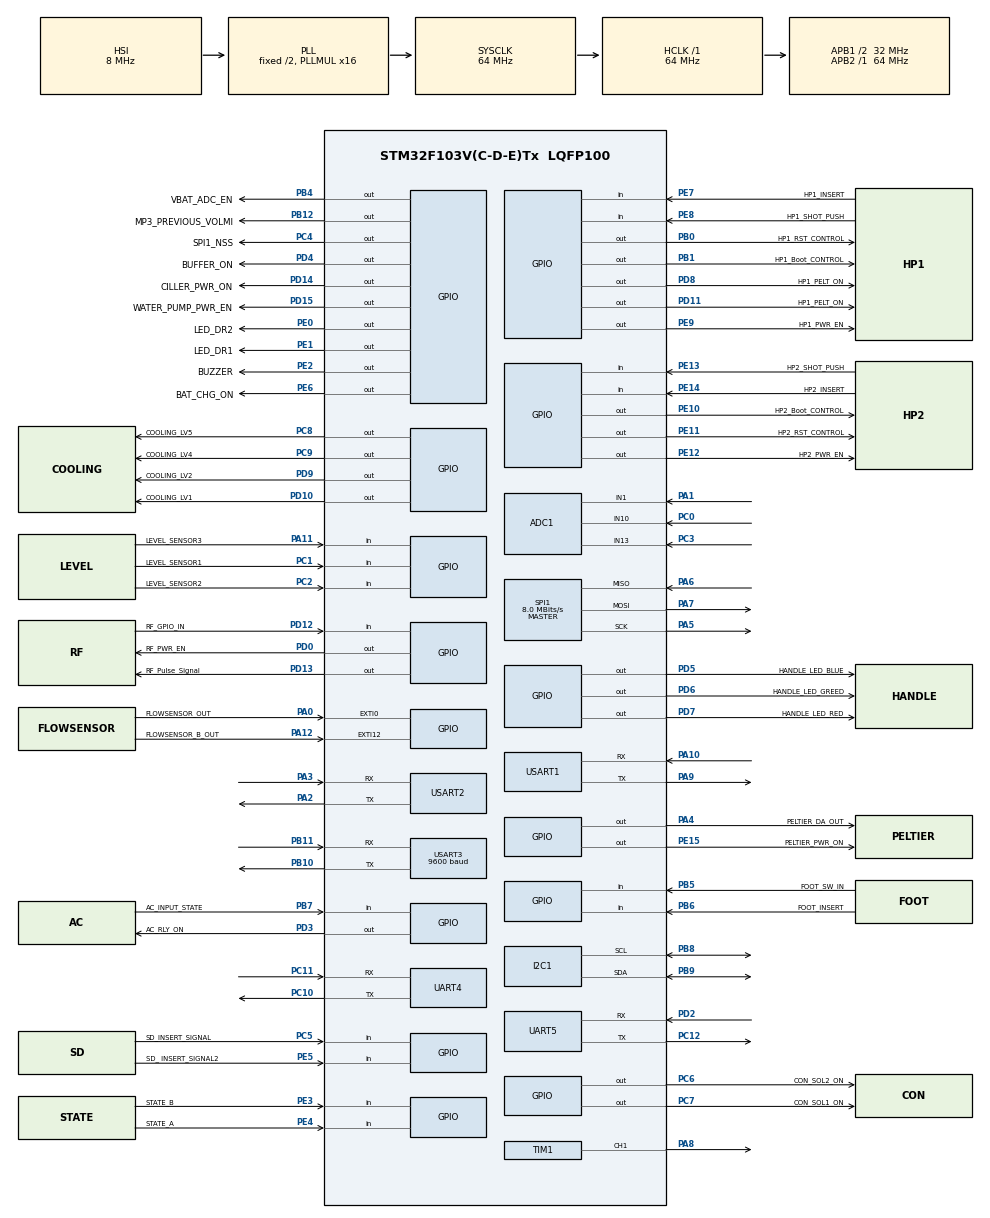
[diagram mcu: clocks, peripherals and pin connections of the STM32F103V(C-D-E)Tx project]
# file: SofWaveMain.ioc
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ADC1.Channel-0\#ChannelRegularConversion=ADC_CHANNEL_10
ADC1.NbrOfConversionFlag=1
ADC1.Rank-0\#ChannelRegularConversion=1
ADC1.SamplingTime-0\#ChannelRegularConversion=ADC_SAMPLETIME_1CYCLE_5
ADC1.master=1
FATFS._USE_LFN=1
Mcu.Family=STM32F1
Mcu.Name=STM32F103V(C-D-E)Tx
Mcu.Package=LQFP100
NVIC.EXTI0_IRQn=true\:0\:0\:false\:false\:true\:true\:true\:true
NVIC.PriorityGroup=NVIC_PRIORITYGROUP_4
NVIC.UART4_IRQn=true\:0\:0\:false\:false\:true\:true\:true\:true
NVIC.UART5_IRQn=true\:0\:0\:false\:false\:true\:true\:true\:true
NVIC.USART1_IRQn=true\:0\:0\:false\:false\:true\:true\:true\:true
NVIC.USART2_IRQn=true\:0\:0\:false\:false\:true\:true\:true\:true
NVIC.USART3_IRQn=true\:0\:0\:false\:false\:true\:true\:true\:true
PA0-WKUP.GPIO_Label=FLOWSENSOR_OUT
PA0-WKUP.Signal=GPXTI0
PA1.Signal=ADCx_IN1
PA10.Mode=Asynchronous
PA10.Signal=USART1_RX
PA11.GPIO_Label=LEVEL_SENSOR3
PA11.Signal=GPIO_Input
PA12.GPIO_Label=FLOWSENSOR_B_OUT
PA12.Signal=GPXTI12
PA13.Mode=Serial_Wire
PA13.Signal=SYS_JTMS-SWDIO
PA14.Mode=Serial_Wire
PA14.Signal=SYS_JTCK-SWCLK
PA2.Mode=Asynchronous
PA2.Signal=USART2_TX
PA3.Mode=Asynchronous
PA3.Signal=USART2_RX
PA4.GPIO_Label=PELTIER_DA_OUT
PA4.Signal=GPIO_Output
PA5.Mode=Full_Duplex_Master
PA5.Signal=SPI1_SCK
PA6.Mode=Full_Duplex_Master
PA6.Signal=SPI1_MISO
PA7.Mode=Full_Duplex_Master
PA7.Signal=SPI1_MOSI
PA8.Signal=S_TIM1_CH1
PA9.Mode=Asynchronous
PA9.Signal=USART1_TX
PB0.GPIO_Label=HP1_RST_CONTROL
PB0.Signal=GPIO_Output
PB1.GPIO_Label=HP1_Boot_CONTROL
PB1.PinState=GPIO_PIN_RESET
PB1.Signal=GPIO_Output
PB10.Mode=Asynchronous
PB10.Signal=USART3_TX
PB11.Mode=Asynchronous
PB11.Signal=USART3_RX
PB12.GPIO_Label=MP3_PREVIOUS_VOLMI
PB12.Signal=GPIO_Output
PB4.GPIO_Label=VBAT_ADC_EN
PB4.Signal=GPIO_Output
PB5.GPIO_Label=FOOT_SW_IN
PB5.Signal=GPIO_Input
PB6.GPIO_Label=FOOT_INSERT
PB6.Signal=GPIO_Input
PB7.GPIO_Label=AC_INPUT_STATE
PB7.Signal=GPIO_Input
PB8.Mode=I2C
PB8.Signal=I2C1_SCL
PB9.Mode=I2C
PB9.Signal=I2C1_SDA
PC0.Signal=ADCx_IN10
PC1.GPIO_Label=LEVEL_SENSOR1
PC1.Signal=GPIO_Input
PC10.Mode=Asynchronous
PC10.Signal=UART4_TX
PC11.Mode=Asynchronous
PC11.Signal=UART4_RX
PC12.Mode=Asynchronous
PC12.Signal=UART5_TX
PC2.GPIO_Label=LEVEL_SENSOR2
PC2.Signal=GPIO_Input
PC3.Signal=ADCx_IN13
PC4.GPIO_Label=SPI1_NSS
PC4.PinState=GPIO_PIN_SET
PC4.Signal=GPIO_Output
PC5.GPIO_Label=SD_INSERT_SIGNAL
PC5.Signal=GPIO_Input
PC6.GPIO_Label=CON_SOL2_ON
PC6.Signal=GPIO_Output
PC7.GPIO_Label=CON_SOL1_ON
PC7.Signal=GPIO_Output
PC8.GPIO_Label=COOLING_LV5
PC8.Signal=GPIO_Output
PC9.GPIO_Label=COOLING_LV4
PC9.Signal=GPIO_Output
PD0.GPIO_Label=RF_PWR_EN
PD0.Signal=GPIO_Output
PD10.GPIO_Label=COOLING_LV1
PD10.Signal=GPIO_Output
PD11.GPIO_Label=HP1_PELT_ON
PD11.Signal=GPIO_Output
PD12.GPIO_Label=RF_GPIO_IN
PD12.Signal=GPIO_Input
PD13.GPIO_Label=RF_Pulse_Signal
PD13.Signal=GPIO_Output
PD14.GPIO_Label=CILLER_PWR_ON
PD14.Signal=GPIO_Output
PD15.GPIO_Label=WATER_PUMP_PWR_EN
PD15.Signal=GPIO_Output
PD2.Mode=Asynchronous
PD2.Signal=UART5_RX
PD3.GPIO_Label=AC_RLY_ON
PD3.Signal=GPIO_Output
PD4.GPIO_Label=BUFFER_ON
PD4.Signal=GPIO_Output
PD5.GPIO_Label=HANDLE_LED_BLUE
PD5.Signal=GPIO_Output
PD6.GPIO_Label=HANDLE_LED_GREED
PD6.Signal=GPIO_Output
PD7.GPIO_Label=HANDLE_LED_RED
PD7.Signal=GPIO_Output
PD8.GPIO_Label=HP1_PELT_ON
PD8.Signal=GPIO_Output
PD9.GPIO_Label=COOLING_LV2
PD9.Signal=GPIO_Output
PE0.GPIO_Label=LED_DR2
PE0.Signal=GPIO_Output
PE1.GPIO_Label=LED_DR1
PE1.Signal=GPIO_Output
PE10.GPIO_Label=HP2_Boot_CONTROL
PE10.Signal=GPIO_Output
PE11.GPIO_Label=HP2_RST_CONTROL
PE11.Signal=GPIO_Output
PE12.GPIO_Label=HP2_PWR_EN
PE12.Signal=GPIO_Output
PE13.GPIO_Label=HP2_SHOT_PUSH
PE13.Signal=GPIO_Input
PE14.GPIO_Label=HP2_INSERT
PE14.Signal=GPIO_Input
PE15.GPIO_Label=PELTIER_PWR_ON
PE15.Signal=GPIO_Output
PE2.GPIO_Label=BUZZER
PE2.Signal=GPIO_Output
PE3.GPIO_Label=STATE_B
PE3.Signal=GPIO_Input
PE4.GPIO_Label=STATE_A
PE4.Signal=GPIO_Input
PE5.GPIO_Label=SD_ INSERT_SIGNAL2
PE5.Signal=GPIO_Input
PE6.GPIO_Label=BAT_CHG_ON
PE6.Signal=GPIO_Output
PE7.GPIO_Label=HP1_INSERT
PE7.Signal=GPIO_Input
PE8.GPIO_Label=HP1_SHOT_PUSH
PE8.Signal=GPIO_Input
PE9.GPIO_Label=HP1_PWR_EN
PE9.Signal=GPIO_Output
ProjectManager.HeapSize=0x200
ProjectManager.StackSize=0x400
ProjectManager.TargetToolchain=STM32CubeIDE
RCC.ADCPresc=RCC_ADCPCLK2_DIV6
RCC.AHBFreq_Value=64000000
RCC.APB1CLKDivider=RCC_HCLK_DIV2
RCC.APB1Freq_Value=32000000
RCC.APB1TimFreq_Value=64000000
RCC.APB2Freq_Value=64000000
RCC.APB2TimFreq_Value=64000000
RCC.HCLKFreq_Value=64000000
RCC.PLLMUL=RCC_PLL_MUL16
RCC.SYSCLKFreq_VALUE=64000000
RCC.SYSCLKSource=RCC_SYSCLKSOURCE_PLLCLK
RCC.USBFreq_Value=64000000
SH.ADCx_IN1.0=ADC1_IN1,IN1
SH.ADCx_IN10.0=ADC1_IN10,IN10
SH.ADCx_IN13.0=ADC1_IN13,IN13
SH.S_TIM1_CH1.0=TIM1_CH1,PWM Generation1 CH1
SPI1.BaudRatePrescaler=SPI_BAUDRATEPRESCALER_8
SPI1.CalculateBaudRate=8.0 MBits/s
SPI1.Direction=SPI_DIRECTION_2LINES
SPI1.Mode=SPI_MODE_MASTER
SPI1.VirtualType=VM_MASTER
TIM1.AutoReloadPreload=TIM_AUTORELOAD_PRELOAD_ENABLE
TIM1.AutomaticOutput=TIM_AUTOMATICOUTPUT_ENABLE
TIM1.Channel-PWM\ Generation1\ CH1=TIM_CHANNEL_1
TIM1.Period=9999
TIM1.Prescaler=63
TIM1.Pulse-PWM\ Generation1\ CH1=5000
UART4.VirtualMode=Asynchronous
UART5.VirtualMode=Asynchronous
USART1.VirtualMode=VM_ASYNC
USART2.VirtualMode=VM_ASYNC
USART3.BaudRate=9600
USART3.VirtualMode=VM_ASYNC
VP_FATFS_VS_Generic.Mode=User_defined
board=custom

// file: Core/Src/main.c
/* USER CODE BEGIN Header */
/**
  ******************************************************************************
  * @file           : main.c
  * @brief          : Main program body
  ******************************************************************************
  * @attention
  *
  * Copyright (c) 2025 STMicroelectronics.
  * All rights reserved.
  *
  * This software is licensed under terms that can be found in the LICENSE file
  * in the root directory of this software component.
  * If no LICENSE file comes with this software, it is provided AS-IS.
  *
  ******************************************************************************
  */
/* USER CODE END Header */
#include "main.h"
#include "adc.h"
#include "fatfs.h"
#include "i2c.h"
#include "spi.h"
#include "tim.h"
#include "usart.h"
#include "gpio.h"

/* USER CODE BEGIN Includes */
#include "common.h"//
/* USER CODE END Includes */

void SystemClock_Config(void);

int main(void)
{

  /* USER CODE BEGIN 1 */
  SCB->VTOR = 0x08010000U;//

  /* USER CODE END 1 */

  /* MCU Configuration--------------------------------------------------------*/

  /* Reset of all peripherals, Initializes the Flash interface and the Systick. */
  HAL_Init();

  /* Configure the system clock */
  SystemClock_Config();

  /* Initialize all configured peripherals */
  MX_GPIO_Init();
  MX_UART5_Init();
  MX_USART1_UART_Init();
  MX_USART2_UART_Init();
  MX_USART3_UART_Init();
  MX_UART4_Init();
  MX_ADC1_Init();
  MX_I2C1_Init();
  MX_SPI1_Init();
  MX_TIM1_Init();
  MX_FATFS_Init();
  /* USER CODE BEGIN 2 */
  Uart_Init();
  Eeprom_All_Read();
  Rf_Init();
  IO_Init();
  Hand_Init();
  LCD_Init();
  SD_Init();

//  HAL_Delay(5000);

  /* USER CODE END 2 */

  /* Infinite loop */
  /* USER CODE BEGIN WHILE */
  while (1)//
  {
    /* USER CODE END WHILE */

    /* USER CODE BEGIN 3 */

#if 1
  IO_Config();//
  UartRxDataProcess();
  Rf_Config();
  Error_Check_Config();
//  SD_Test();

#else

#endif

  }
  /* USER CODE END 3 */
}

void SystemClock_Config(void)
{
  RCC_OscInitTypeDef RCC_OscInitStruct = {0};
  RCC_ClkInitTypeDef RCC_ClkInitStruct = {0};
  RCC_PeriphCLKInitTypeDef PeriphClkInit = {0};

  /** Initializes the RCC Oscillators according to the specified parameters
  * in the RCC_OscInitTypeDef structure.
  */
  RCC_OscInitStruct.OscillatorType = RCC_OSCILLATORTYPE_HSI;
  RCC_OscInitStruct.HSIState = RCC_HSI_ON;
  RCC_OscInitStruct.HSICalibrationValue = RCC_HSICALIBRATION_DEFAULT;
  RCC_OscInitStruct.PLL.PLLState = RCC_PLL_ON;
  RCC_OscInitStruct.PLL.PLLSource = RCC_PLLSOURCE_HSI_DIV2;
  RCC_OscInitStruct.PLL.PLLMUL = RCC_PLL_MUL16;
  if (HAL_RCC_OscConfig(&RCC_OscInitStruct) != HAL_OK)
  {
    Error_Handler();
  }

  /** Initializes the CPU, AHB and APB buses clocks
  */
  RCC_ClkInitStruct.ClockType = RCC_CLOCKTYPE_HCLK|RCC_CLOCKTYPE_SYSCLK
                              |RCC_CLOCKTYPE_PCLK1|RCC_CLOCKTYPE_PCLK2;
  RCC_ClkInitStruct.SYSCLKSource = RCC_SYSCLKSOURCE_PLLCLK;
  RCC_ClkInitStruct.AHBCLKDivider = RCC_SYSCLK_DIV1;
  RCC_ClkInitStruct.APB1CLKDivider = RCC_HCLK_DIV2;
  RCC_ClkInitStruct.APB2CLKDivider = RCC_HCLK_DIV1;

  if (HAL_RCC_ClockConfig(&RCC_ClkInitStruct, FLASH_LATENCY_2) != HAL_OK)
  {
    Error_Handler();
  }
  PeriphClkInit.PeriphClockSelection = RCC_PERIPHCLK_ADC;
  PeriphClkInit.AdcClockSelection = RCC_ADCPCLK2_DIV6;
  if (HAL_RCCEx_PeriphCLKConfig(&PeriphClkInit) != HAL_OK)
  {
    Error_Handler();
  }
}

void Error_Handler(void)
{
  __disable_irq();
  while (1)
  {
  }
}
